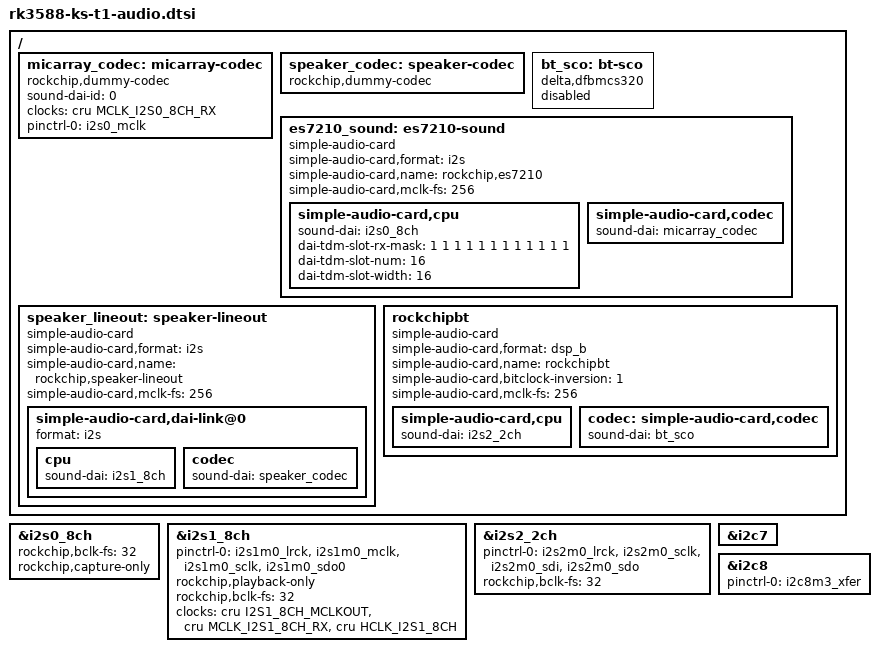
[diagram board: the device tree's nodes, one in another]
/ {
    micarray_codec:micarray-codec {
		compatible = "rockchip,dummy-codec";
		#sound-dai-cells = <0>;
		sound-dai-id = <0>;
		status = "disabled";
	};

	speaker_codec: speaker-codec {
		status = "disabled";
		compatible = "rockchip,dummy-codec";
		#sound-dai-cells = <0>;
	};

	bt_sco: bt-sco {
            compatible = "delta,dfbmcs320";
            #sound-dai-cells = <0>;
            status = "disabled";
    };

	es7210_sound:es7210-sound {
		status = "disabled";
		compatible = "simple-audio-card";
		simple-audio-card,format = "i2s";   // 需要支持12通道
		simple-audio-card,name = "rockchip,es7210";
		simple-audio-card,mclk-fs = <256>;
		//simple-audio-card,mic-det-gpio = <&gpio4 RK_PA4 GPIO_ACTIVE_HIGH>;
		simple-audio-card,cpu {
				sound-dai = <&i2s0_8ch>;
				dai-tdm-slot-rx-mask = <1 1 1 1 1 1 1 1 1 1 1 1>;
				dai-tdm-slot-num = <16>;     // tdm 12 通道
				dai-tdm-slot-width = <16>;
		};
		simple-audio-card,codec {
			sound-dai = <&micarray_codec>;
		};
	};

	speaker_lineout: speaker-lineout {
		status = "disabled";
		compatible = "simple-audio-card";
		simple-audio-card,format = "i2s";
		simple-audio-card,name = "rockchip,speaker-lineout";
		simple-audio-card,mclk-fs = <256>;
		//simple-audio-card,mic-det-gpio = <&gpio4 RK_PA7 GPIO_ACTIVE_HIGH>;
		simple-audio-card,dai-link@0 {
			format = "i2s";
			cpu {
				sound-dai = <&i2s1_8ch>;
			};
			codec {
				sound-dai = <&speaker_codec>;
			};
		};
	};

	rockchipbt:rockchipbt {
		compatible = "simple-audio-card";
        simple-audio-card,format = "dsp_b";
        simple-audio-card,name = "rockchipbt";
        simple-audio-card,bitclock-inversion = <1>;
        //simple-audio-card,bitclock-master = <&codec>;
        //simple-audio-card,frame-master = <&codec>;
        simple-audio-card,mclk-fs = <256>;
        status = "disabled";
        simple-audio-card,cpu {
            sound-dai = <&i2s2_2ch>;
        };

        codec: simple-audio-card,codec {
            sound-dai = <&bt_sco>;
        };
	};

};

&i2s0_8ch {
	status = "okay";
    //#sound-dai-cells = <0>;
	//rockchip,clk-trcm = <0>;
	rockchip,bclk-fs = <32>;
	rockchip,capture-only;
};

&i2s1_8ch {
	pinctrl-names = "default";
	pinctrl-0 = <&i2s1m0_lrck
		&i2s1m0_mclk
		&i2s1m0_sclk
		&i2s1m0_sdo0>;
	status = "okay";
    rockchip,playback-only;
    rockchip,bclk-fs = <32>;
	clocks = <&cru I2S1_8CH_MCLKOUT>, <&cru MCLK_I2S1_8CH_RX>, <&cru HCLK_I2S1_8CH>;
    clock-names = "mclk_tx", "mclk_rx", "hclk";
};

&i2s2_2ch {
	pinctrl-names = "default";
	pinctrl-0 = <&i2s2m0_lrck
				&i2s2m0_sclk
				&i2s2m0_sdi
				&i2s2m0_sdo>;
	status = "okay";
	rockchip,bclk-fs = <32>;
};

&micarray_codec {
	clocks = <&cru MCLK_I2S0_8CH_RX>;
	clock-names = "mclk";
	pinctrl-names = "default";
	pinctrl-0 = <&i2s0_mclk>;
	status = "okay";
};

&speaker_codec {
	status = "okay";
};

&bt_sco {
	status = "disabled";
};

&es7210_sound {
	status = "okay";
};

&speaker_lineout {
	status = "okay";
};

&rockchipbt {
	status = "okay";
};


&i2c7 {
	status = "okay";
};

&i2c8 {
    pinctrl-names = "default";
	pinctrl-0 = <&i2c8m3_xfer>;
	status = "okay";
};
